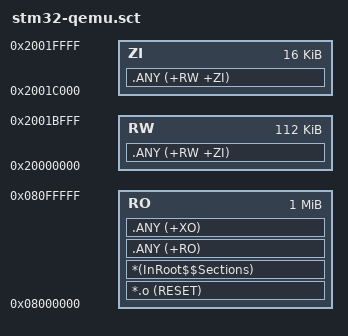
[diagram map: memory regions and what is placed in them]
; *************************************************************
; *** Scatter-Loading Description File generated by uVision ***
; *************************************************************

LR_IROM1 0x08000000 0x00100000  {    ; load region size_region
  RO 0x08000000 0x00100000  {  ; load address = execution address
   *.o (RESET)
   *(InRoot$$Sections)
   .ANY (+RO)
   .ANY (+XO)
  }
  RW 0x20000000 0x0001C000  {  ; RW data
   .ANY (+RW +ZI)
  }
  ZI 0x2001C000 0x00004000  {
   .ANY (+RW +ZI)
  }
}

